# CS32F031x register map
File version: 1.0
Registers are 32-bit, read-write, reset 0x0 unless marked. A register's access mark holds for its fields unless they carry their own. Offsets are from the block's base; [hi:lo] are bit positions.

## RCU — Reset and clock unit
Base 0x40021000
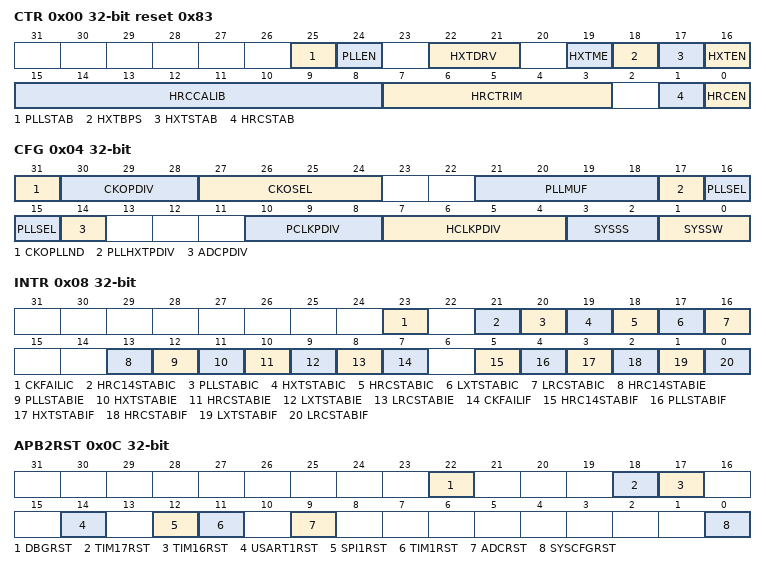
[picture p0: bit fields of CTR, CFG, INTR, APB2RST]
0x00 CTR access per field reset 0x83 — Clock control register
  [25] PLLSTAB ro — PLL Stabilization flag
  [24] PLLEN rw — PLL enable
  [22:21] HXTDRV rw — HXT Drive capability Selection
  [19] HXTME rw — HXT Monitor Enable
  [18] HXTBPS rw — HXT Bypass Enable
  [17] HXTSTAB ro — HXT Stabilization flag
  [16] HXTEN rw — HXT Enable
  [15:8] HRCCALIB ro — HRC Internal 8MHz RC calibration
  [7:3] HRCTRIM rw — HRC Triming
  [1] HRCSTAB ro — HRC Stabilization flag
  [0] HRCEN rw — HRC Enable
0x04 CFG access per field — Clock configuration register
  [31] CKOPLLND rw — PLL clock not divided for CLKOUT
  [30:28] CKOPDIV rw — CLKOUT Pre-divider
  [27:24] CKOSEL rw — CLKOUT Source Selection
  [21:18] PLLMUF rw — PLL clock multiplication factor
  [17] PLLHXTPDIV rw — PLL source HXT pre-divdier
  [16:15] PLLSEL rw — PLL source Selction
  [14] ADCPDIV rw — ADC Clock Pre-divider
  [10:8] PCLKPDIV rw — PCLK Pre-divider
  [7:4] HCLKPDIV rw — HCLK Pre-divider
  [3:2] SYSSS ro — System clock switch status
  [1:0] SYSSW rw — System clock switch Control
0x08 INTR access per field — Clock interrupt register
  [23] CKFAILIC wo — HXT Clock Fail Interrupt Clear
  [21] HRC14STABIC wo — HRC14 stabilization Interrupt Clear
  [20] PLLSTABIC wo — PLL stabilization Interrupt Clear
  [19] HXTSTABIC wo — HXT stabilization Interrupt Clear
  [18] HRCSTABIC wo — HRC stabilization Interrupt Clear
  [17] LXTSTABIC wo — LXT stabilization Interrupt Clear
  [16] LRCSTABIC wo — LRC stabilization Interrupt Clear
  [13] HRC14STABIE rw — HRC14 stabilization Interrupt Enable
  [12] PLLSTABIE rw — PLL stabilization Interrupt Enable
  [11] HXTSTABIE rw — HXT stabilization Interrupt Enable
  [10] HRCSTABIE rw — HRC stabilization Interrupt Enable
  [9] LXTSTABIE rw — LXT stabilization interrupt enable
  [8] LRCSTABIE rw — LRC stabilization interrupt enable
  [7] CKFAILIF ro — HXT clock fail interrupt flag
  [5] HRC14STABIF ro — HRC14 stabilization interrupt flag
  [4] PLLSTABIF ro — PLL stabilization interrupt flag
  [3] HXTSTABIF ro — HXT stabilization interrupt flag
  [2] HRCSTABIF ro — HRC stabilization interrupt flag
  [1] LXTSTABIF ro — LXT stabilization interrupt flag
  [0] LRCSTABIF ro — LRC stabilization interrupt flag
0x0C APB2RST — APB2 reset register
  [22] DBGRST — Debug MCU reset
  [18] TIM17RST — TIM17 timer reset
  [17] TIM16RST — TIM16 timer reset
  [14] USART1RST — USART1 reset
  [12] SPI1RST — SPI 1 reset
  [11] TIM1RST — TIM1 timer reset
  [9] ADCRST — ADC interface reset
  [0] SYSCFGRST — SYSCFG reset
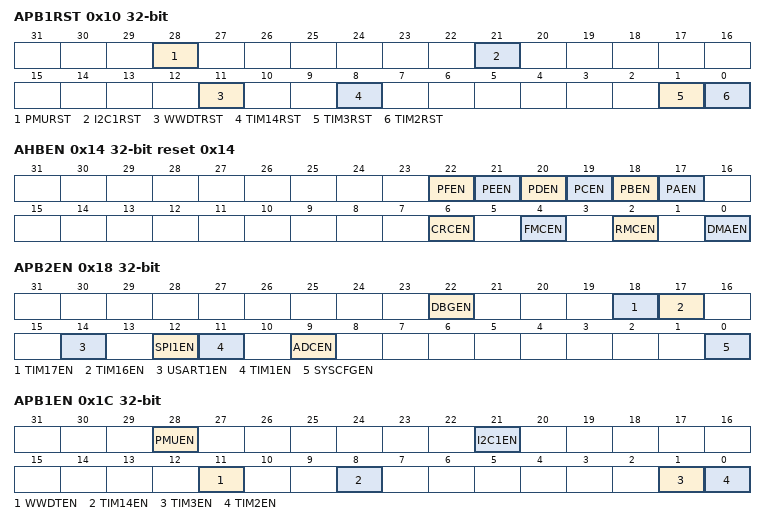
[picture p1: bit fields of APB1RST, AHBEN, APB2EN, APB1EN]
0x10 APB1RST — APB1 reset register
  [28] PMURST — PMU reset
  [21] I2C1RST — I2C1 reset
  [11] WWDTRST — WWDT reset
  [8] TIM14RST — Timer 14 reset
  [1] TIM3RST — Timer 3 reset
  [0] TIM2RST — Timer 2 reset
0x14 AHBEN reset 0x14 — AHB Clock enable register
  [22] PFEN — enable bit for GPIO port F clock
  [21] PEEN — enable bit for GPIO port E clock
  [20] PDEN — enable bit for GPIO port D clock
  [19] PCEN — enable bit for GPIO port C clock
  [18] PBEN — enable bit for GPIO port B clock
  [17] PAEN — enable bit for GPIO port A clock
  [6] CRCEN — enable bit for CRC clock
  [4] FMCEN — enable bit for FMC clock
  [2] RMCEN — enable bit for SRAM clock
  [0] DMAEN — enable bit for DMA clock
0x18 APB2EN — APB peripheral clock enable register 2
  [22] DBGEN — enable bit for DBG clock
  [18] TIM17EN — enable bit for TIM17 clock
  [17] TIM16EN — enable bit for TIM16 clock
  [14] USART1EN — enable bit for USART1 clock
  [12] SPI1EN — enable bit for SPI1 clock
  [11] TIM1EN — enable bit for TIM1 clock
  [9] ADCEN — enable bit for ADC clock
  [0] SYSCFGEN — enable bit for SYSCFG clock
0x1C APB1EN — APB peripheral clock enable register 1
  [28] PMUEN — enable bit for PMU clock
  [21] I2C1EN — enable bit for I2C1 clock
  [11] WWDTEN — enable bit for WWDT clock
  [8] TIM14EN — enable bit for TIM14 clock
  [1] TIM3EN — enable bit for TIM3 clock
  [0] TIM2EN — Tenable bit for TIM2 clock
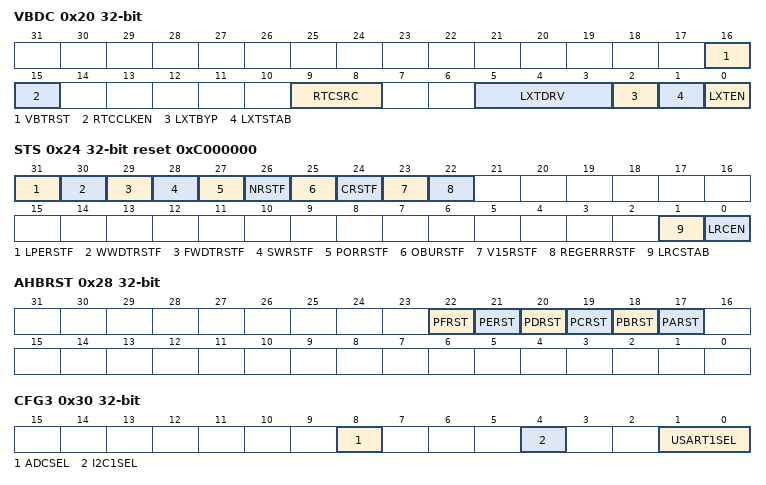
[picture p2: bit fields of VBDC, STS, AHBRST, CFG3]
0x20 VBDC access per field — VBAT domain control register
  [16] VBTRST rw — VBAT domain software reset
  [15] RTCCLKEN rw — RTC clock enable
  [9:8] RTCSRC rw — RTC clock source selection
  [5:3] LXTDRV rw — LXT oscillator drive capability
  [2] LXTBYP rw — LXT bypass
  [1] LXTSTAB ro — LXT Stabilization flag
  [0] LXTEN rw — LXT Enable
0x24 STS access per field reset 0xC000000 — status register
  [31] LPERSTF rw — Low-power mode enter-reset flag
  [30] WWDTRSTF rw — WWDT reset flag
  [29] FWDTRSTF rw — FWDT reset flag
  [28] SWRSTF rw — Software reset flag
  [27] PORRSTF rw — POR/PDR reset flag
  [26] NRSTF rw — reset flag of pin nRST
  [25] OBURSTF rw — Option byte update reset flag
  [24] CRSTF rw — Clear reset flag
  [23] V15RSTF ro — Reset flag from the 1.5V domain
  [22] REGERRRSTF ro — register error flag
  [1] LRCSTAB ro — LRC Stabilization flag
  [0] LRCEN rw — LRC enable
0x28 AHBRST — AHB reset register
  [22] PFRST — GPIO port F reset
  [21] PERST — GPIO port E reset
  [20] PDRST — GPIO port D reset
  [19] PCRST — GPIO port C reset
  [18] PBRST — GPIO port B reset
  [17] PARST — GPIO port A reset
0x2C CFG2 — Clock configuration register 2
  [3:0] PLLPDIV — PLL pre-divider factor
0x30 CFG3 — Clock configuration register 3
  [8] ADCSEL — Selection of ADC Clock
  [4] I2C1SEL — Selection of I2C1 Clock
  [1:0] USART1SEL — Selection of USART1 Clock
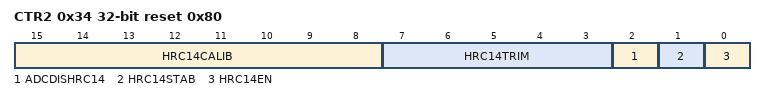
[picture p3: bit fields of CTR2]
0x34 CTR2 access per field reset 0x80 — Clock control register 2
  [15:8] HRC14CALIB ro — HRC14 calibration
  [7:3] HRC14TRIM rw — HRC14 Triming
  [2] ADCDISHRC14 rw — ADC control HRC14 opening disable
  [1] HRC14STAB ro — HRC14 Stabilization flag
  [0] HRC14EN rw — HRC14 enable
